# SSE310 register map
Vendor: ARM Ltd.; Series: ARMv8.1-M Mainline; File version: 1.0
CPU: CM85 r0p0, little endian, MPU, FPU, 3 interrupt priority bits, 8 SAU regions
Registers are 32-bit, read-write, reset 0x0 unless marked. A register's access mark holds for its fields unless they carry their own. Offsets are from the block's base; [hi:lo] are bit positions; {n}, {i} and the like mark numbered series; 'fields as' and 'values as' point back to an identical list.

## SYSCONTROL — System Control
Base 0x58021000
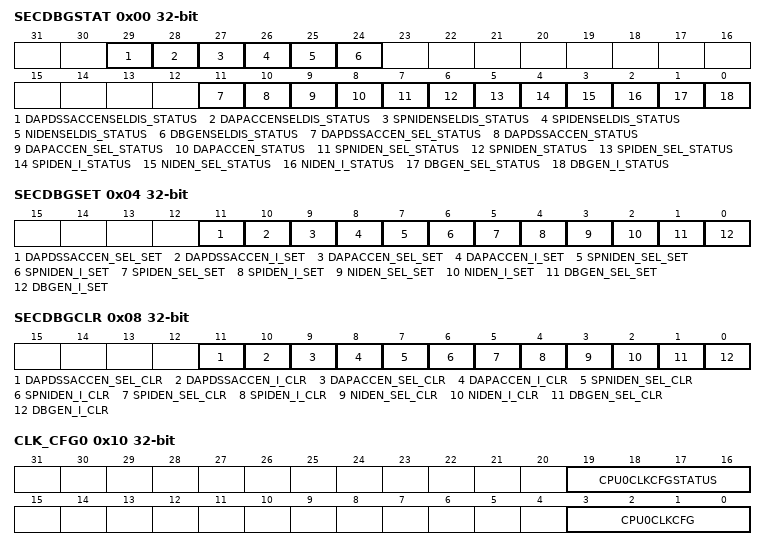
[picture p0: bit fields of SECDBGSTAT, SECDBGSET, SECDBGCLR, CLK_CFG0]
0x00 SECDBGSTAT ro — Secure Debug Configuration Status
  [29] DAPDSSACCENSELDIS_STATUS — Returns the DAPDSSACCENSELDIS configuration value when read.
    1=enable (Secure privilege non-invasive debug enable selector); 0=disable (Secure privilege non-invasive debug disable selector)
  [28] DAPACCENSELDIS_STATUS — Returns the DAPACCENSELDIS configuration value when read.
    values as DAPDSSACCENSELDIS_STATUS
  [27] SPNIDENSELDIS_STATUS — Returns the SPNIDENSELDIS configuration value when read.
    values as DAPDSSACCENSELDIS_STATUS
  [26] SPIDENSELDIS_STATUS — Returns the SPIDENSELDIS configuration value when read.
    values as DAPDSSACCENSELDIS_STATUS
  [25] NIDENSELDIS_STATUS — Returns the NIDENSELDIS configuration value when read.
    values as DAPDSSACCENSELDIS_STATUS
  [24] DBGENSELDIS_STATUS — Returns the DBGENSELDIS configuration value when read.
    values as DAPDSSACCENSELDIS_STATUS
  [11] DAPDSSACCEN_SEL_STATUS — Active High DAP to Debug Subsystem Access Enable Selector Value. This bit returns the DAPDSSACCEN_SEL value. Forced to Zero if DAPDSSACCENSELDIS = 1.
    values as DAPDSSACCENSELDIS_STATUS
  [10] DAPDSSACCEN_STATUS — Active High DAP to Debug Subsystem Access Enable Value. This bit reflects the value on the DAPDSSACCEN pin.
    values as DAPDSSACCENSELDIS_STATUS
  [9] DAPACCEN_SEL_STATUS — Active High DAP Access Enable Selector Value. This bit returns the DAPACCEN_SEL value. Forced to Zero if DAPACCENSELDIS = 1.
    values as DAPDSSACCENSELDIS_STATUS
  [8] DAPACCEN_STATUS — Active High DAP Access Enable Value. This bit reflects the value on the DAPACCEN pin.
    values as DAPDSSACCENSELDIS_STATUS
  [7] SPNIDEN_SEL_STATUS — Secure privilege non-invasive debug enable selector value
    values as DAPDSSACCENSELDIS_STATUS
  [6] SPNIDEN_STATUS — Secure privilege non-invasive debug enable value
    1=enable (Secure privilege non-invasive debug enable); 0=disable (Secure privilege non-invasive debug disable)
  [5] SPIDEN_SEL_STATUS — Secure privilege invasive debug enable selector value
    1=enable (Secure privilege invasive debug enable selector); 0=disable (Secure privilege invasive debug disable selector)
  [4] SPIDEN_I_STATUS — Secure privilege invasive debug enable value
    1=enable (Secure privilege invasive debug enable); 0=disable (Secure privilege invasive debug disable)
  [3] NIDEN_SEL_STATUS — Non-invasive debug enable selector value
    1=enable (non-invasive debug enable selector); 0=disable (non-invasive debug disable selector)
  [2] NIDEN_I_STATUS — Non-invasive debug enable value
    1=enable (non-invasive debug enable); 0=disable (non-invasive debug disable)
  [1] DBGEN_SEL_STATUS — Debug enable selector value
    1=enable (debug enable selector); 0=disable (debug disable selector)
  [0] DBGEN_I_STATUS — Debug enable value
    1=enable (debug enable); 0=disable (debug disable)
0x04 SECDBGSET wo — Secure Debug Configuration Set
  [11] DAPDSSACCEN_SEL_SET — Set Active High DAP to Debug Subsystem Access Enable Selector. Write HIGH to set DAPDSSACCEN_SEL. RAZWI if DAPDSSACCENSELDIS = 1.
    values as SECDBGSTAT.DAPDSSACCENSELDIS_STATUS
  [10] DAPDSSACCEN_I_SET — Set internal version of Active High DAP to Debug Subsystem Access Enable. Write HIGH to set DAPDSSACCEN_I. When read returns DAPDSSACCEN_I. RAZWI if DAPDSSACCENSELDIS = 1.
    values as SECDBGSTAT.DAPDSSACCENSELDIS_STATUS
  [9] DAPACCEN_SEL_SET — Set Active High DAP Access Enable Selector. Write HIGH to set DAPACCEN_SEL. RAZWI if DAPACCENSELDIS = 1.
    values as SECDBGSTAT.DAPDSSACCENSELDIS_STATUS
  [8] DAPACCEN_I_SET — Set internal version of Active High DAP Access Enable. Write HIGH to set DAPACCEN_I. When read returns DAPACCEN_I. RAZWI if DAPACCENSELDIS = 1.
    values as SECDBGSTAT.DAPDSSACCENSELDIS_STATUS
  [7] SPNIDEN_SEL_SET — Secure privilege non-invasive debug enable selector set control
    1=enable (Secure privilege non-invasive debug enable selector set control); 0=disable (Secure privilege non-invasive debug disable selector set control)
  [6] SPNIDEN_I_SET — Secure privilege non-invasive debug enable set control
    1=enable (Secure privilege non-invasive debug enable set control); 0=disable (Secure privilege non-invasive debug disable set control)
  [5] SPIDEN_SEL_SET — Secure privilege invasive debug enable selector set control
    1=enable (Secure privilege invasive debug enable selector set control); 0=disable (Secure privilege invasive debug disable selector set control)
  [4] SPIDEN_I_SET — Secure privilege invasive debug enable set control
    1=enable (Secure privilege invasive debug enable set control); 0=disable (Secure privilege invasive debug disable set control)
  [3] NIDEN_SEL_SET — Non-invasive debug enable selector set control
    1=enable (non-invasive debug enable selector set control); 0=disable (non-invasive debug disable selector set control)
  [2] NIDEN_I_SET — Non-invasive debug enable set control
    1=enable (non-invasive debug enable set control); 0=disable (non-invasive debug disable set control)
  [1] DBGEN_SEL_SET — Debug enable selector set control
    1=enable (debug enable selector set control); 0=disable (debug disable selector set control)
  [0] DBGEN_I_SET — High active debug enable set control
0x08 SECDBGCLR wo — Secure Debug Configuration Clear
  [11] DAPDSSACCEN_SEL_CLR — Clear Active High DAP to Debug Subsystem Access Enable Selector. Write HIGH to clear DAPDSSACCEN_SEL. RAZWI if DAPDSSACCENSELDIS = 1.
    values as SECDBGSTAT.DAPDSSACCENSELDIS_STATUS
  [10] DAPDSSACCEN_I_CLR — Clears internal version of Active High DAP to Debug Subsystem Access Enable. Write HIGH to clear DAPDSSACCEN_I. Always RAZ. WI if DAPDSSACCENSELDIS = 1.
    values as SECDBGSTAT.DAPDSSACCENSELDIS_STATUS
  [9] DAPACCEN_SEL_CLR — Clear Active High DAP Access Enable Selector. Write HIGH to clear DAPACCEN_SEL. RAZWI if DAPACCENSELDIS = 1.
    values as SECDBGSTAT.DAPDSSACCENSELDIS_STATUS
  [8] DAPACCEN_I_CLR — Clear internal version of Active High DAP Access Enable. Write HIGH to clear DAPACCEN_I. When read returns DAPACCEN_I. RAZWI if DAPACCENSELDIS = 1.
    values as SECDBGSTAT.DAPDSSACCENSELDIS_STATUS
  [7] SPNIDEN_SEL_CLR — Secure privilege non-invasive debug enable selector clear control
    1=enable (Secure privilege non-invasive debug enable selector clear control); 0=disable (Secure privilege non-invasive debug disable selector clear control)
  [6] SPNIDEN_I_CLR — Secure privilege non-invasive debug enable clear control
    1=enable (Secure privilege non-invasive debug enable clear control); 0=disable (Secure privilege non-invasive debug disable clear control)
  [5] SPIDEN_SEL_CLR — Secure privilege invasive debug enable selector clear control
    1=enable (Secure privilege invasive debug enable selector clear control); 0=disable (Secure privilege invasive debug disable selector clear control)
  [4] SPIDEN_I_CLR — Secure privilege invasive debug enable clear control
    1=enable (Secure privilege invasive debug enable clear control); 0=disable (Secure privilege invasive debug disable clear control)
  [3] NIDEN_SEL_CLR — Non-invasive debug enable selector clear control
    1=enable (non-invasive debug enable selector clear control); 0=disable (non-invasive debug disable selector clear control)
  [2] NIDEN_I_CLR — Non-invasive debug enable clear control
    1=enable (non-invasive debug enable clear control); 0=disable (non-invasive debug disable clear control)
  [1] DBGEN_SEL_CLR — Debug enable selector clear control
    1=enable (debug enable selector clear control); 0=disable (debug disable selector clear control)
  [0] DBGEN_I_CLR — Debug enable clear control
    1=enable (debug enable clear control); 0=disable (debug disable clear control)
0x0C SCSECCTRL — System Security Control
  [2] SCSECCFGLOCK — Control to disable writes to security-related control registers in this register block
    1=disable (control to disable writes to security-related control registers in this register block); 0=enable (control to enable writes to security-related control registers in this register block)
0x10 CLK_CFG0 — Clock Configuration Register 0.
  [19:16] CPU0CLKCFGSTATUS ro — Clock Configuration Status value that reports the status of clock control for CPU0CLK.
  [3:0] CPU0CLKCFG — Clock Configuration value that drives CPU0CLKCFG signals.
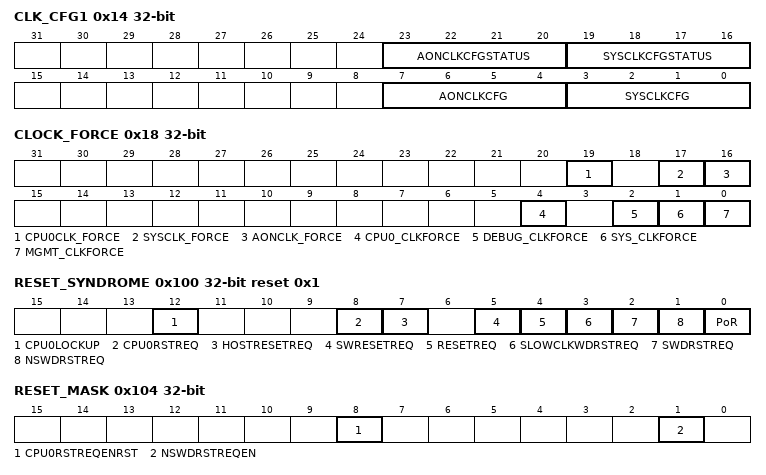
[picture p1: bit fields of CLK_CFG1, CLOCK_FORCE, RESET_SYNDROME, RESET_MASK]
0x14 CLK_CFG1 — Clock Configuration Register 1.
  [23:20] AONCLKCFGSTATUS — Clock Configuration Status value that reports the status of clock control for AONCLK.
  [19:16] SYSCLKCFGSTATUS ro — Clock Configuration Status value that reports the status of clock control for SYSCLK.
  [7:4] AONCLKCFG — Clock Configuration value that drives AONCLKCFG signals.
  [3:0] SYSCLKCFG — Clock Configuration value that drives SYSCLKCFG signals.
0x18 CLOCK_FORCE
  [19] CPU0CLK_FORCE — Set HIGH to request the input CPU0CLK source to stay ON..
  [17] SYSCLK_FORCE — Set HIGH to request the input SYSCLK source to stay ON.
  [16] AONCLK_FORCE — Set HIGH to request the input AONCLK source to stay ON.
  [4] CPU0_CLKFORCE — Set HIGH to force PD_CPU0 Local clocks to run.
  [2] DEBUG_CLKFORCE — Set HIGH to force all clocks in PD_DEBUG to run.
  [1] SYS_CLKFORCE — Set HIGH to force all clocks in PD_SYS to run.
  [0] MGMT_CLKFORCE — Set HIGH to force all clocks in PD_AON domain that runs on SYSCLK to run.
0x100 RESET_SYNDROME reset 0x1
  [12] CPU0LOCKUP wo — CPU 0 Lockup Status.
  [8] CPU0RSTREQ wo — CPU 0 Warm Reset Request.
  [7] HOSTRESETREQ wo — Host Level Cold Reset Request Input.
  [5] SWRESETREQ wo — Software Cold Reset Request.
  [4] RESETREQ wo — Subsystem Hardware Cold Reset Request Input.
  [3] SLOWCLKWDRSTREQ wo — SLOWCLK Watchdog Cold Reset Request.
  [2] SWDRSTREQ wo — Secure Watchdog Cold Reset Request.
  [1] NSWDRSTREQ wo — Non-Secure Watchdog Cold Reset Request.
  [0] PoR wo — Power-on
0x104 RESET_MASK
  [8] CPU0RSTREQENRST — CPU 0 Warm Reset Request Enable.
    1=enabled (Enable Merging CPU 0 System Reset Request); 0=Disabled Merging CPU 0 System Reset Request
  [1] NSWDRSTREQEN — Enable NON-SECURE WATCHDOG Reset
    1=enabled (Enable NON-SECURE WATCHDOG Reset); 0=Disabled NON-SECURE WATCHDOG Reset
0x108 SWRESET wo — Software Reset
  [9] SWRESETREQ — High Active Software Reset Request
0x10C GRETREG — General Purpose Retention
  [15:0] GRETREG — General Purpose Retention Register
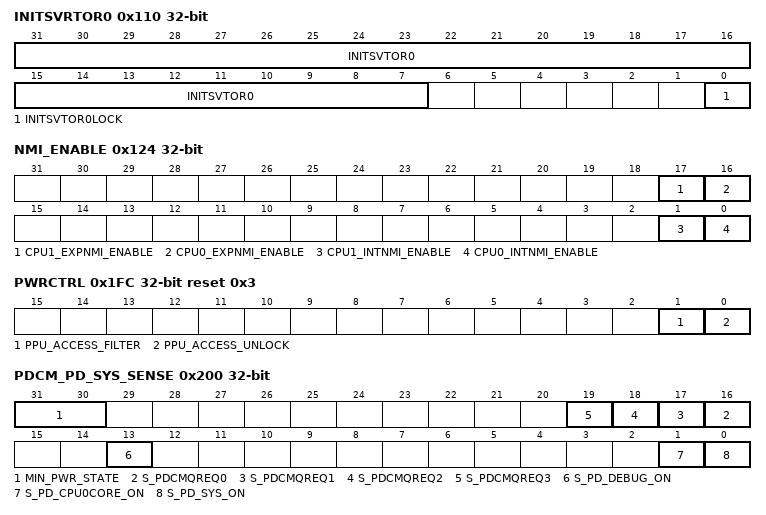
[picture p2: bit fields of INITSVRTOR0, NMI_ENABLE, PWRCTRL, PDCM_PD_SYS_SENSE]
0x110 INITSVRTOR0 — Initial Secure Reset Vector Register For CPU 0
  [31:7] INITSVTOR0 — Default Secure Vector table offset at reset for CPU 0
  [0] INITSVTOR0LOCK wo — Lock INITSVTOR0. When set to 1, will stop any further writes to INITSVTOR0 and INITSVTOR0LOCK fields. Cleared only by Warm reset.
0x120 CPUWAIT — CPU Boot wait control after reset
  [0] CPU0WAIT — CPU 0 waits at boot and whether CPU1 powers up
    0=normally_or_powerup (CPU0 boot normally. From Power ON reset, nSRST reset or Watchdog Reset, CPU 1 powers up); 1=wait_or_no_powerup (CPU0 wait. From Power ON reset, nSRST reset or Watchdog Reset, CPU 1 do not power up)
0x124 NMI_ENABLE
  [17] CPU1_EXPNMI_ENABLE — CPU1 Externally Sourced NMI Enable
    1=enable (CPU1 Externally Sourced NMI Enabled); 0=disabled (CPU1 Externally Sourced NMI Disabled)
  [16] CPU0_EXPNMI_ENABLE — CPU0 Externally Sourced NMI Enable
    1=enable (CPU0 Externally Sourced NMI Enabled); 0=disabled (CPU0 Externally Sourced NMI Disabled)
  [1] CPU1_INTNMI_ENABLE — CPU1 Internally Sourced NMI Enable
    1=enable (CPU1 Internally Sourced NMI Enabled); 0=disabled (CPU1 Internally Sourced NMI Disabled)
  [0] CPU0_INTNMI_ENABLE — CPU0 Internally Sourced NMI Enable
    1=enable (CPU0 Internally Sourced NMI Enabled); 0=disabled (CPU0 Internally Sourced NMI Disabled)
0x1FC PWRCTRL reset 0x3 — Power Configuration and Control.
  [1] PPU_ACCESS_FILTER — Filter Access to PPU Registers. When set to '1' only key PPU interrupt handling registers are open to write access, and all other PPU registers are read only. When set to '0' releases all PPU register to full access.
  [0] PPU_ACCESS_UNLOCK wo — PPU_ACCESS_FILTER write unlock. When 1, Both PPU_ACCESS_FILTER and this register bits can be written. When set to '0' the PPU_ACCESS_FILTER and this register bit will no longer writable, and PPU_ACCESS_UNLOCK will stay '0'.
0x200 PDCM_PD_SYS_SENSE — External Wakeup Control
  [31:30] MIN_PWR_STATE — Defines the Minimum Power State, when PD_SYS is trying to enter a lower power state.
  [n+16] S_PDCMQREQ{n} (n=0..3) — Enable PDCMQREQn[{n}] signal Sensitivity
    1=Enable PDCMQREQn[{n}] signal Sensitivity; 0=disabled (Disable PDCMQREQn[{n}] signal Sensitivity.)
  [13] S_PD_DEBUG_ON ro — Tied to LOW
  [1] S_PD_CPU0CORE_ON ro — Tied to HIGH
    1=high (PD_SYS always tries to stay ON if PD_CPU0CORE is ON)
  [0] S_PD_SYS_ON — Enable PD_SYS ON Sensitivity
    1=enable (Keep PD_SYS awake after powered ON)
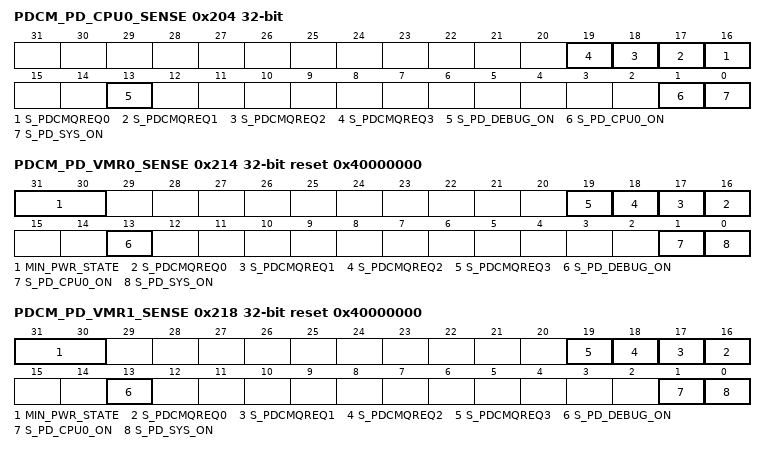
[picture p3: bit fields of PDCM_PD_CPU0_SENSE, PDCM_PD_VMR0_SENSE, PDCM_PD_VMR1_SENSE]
0x204 PDCM_PD_CPU0_SENSE — PDCM PD_CPU0 Sensitivity.
  [n+16] S_PDCMQREQ{n} (n=0..3) — PDCMQREQn[{n}] Tied to LOW
  [13] S_PD_DEBUG_ON ro — Tied to LOW
  [1] S_PD_CPU0_ON ro — Tied to LOW
  [0] S_PD_SYS_ON — Enable PD_SYS ON Sensitivity
    1=enable (Keep PD_SYS awake after powered ON)
0x214 PDCM_PD_VMR0_SENSE reset 0x40000000 — PDCM PD_VMR0 Sensitivity.
  [31:30] MIN_PWR_STATE — Defines the Minimum Power State, when PD_SYS is trying to enter a lower power state.
  [n+16] S_PDCMQREQ{n} (n=0..3) — Enable PDCMQREQn[{n}] signal Sensitivity
    values as PDCM_PD_SYS_SENSE.S_PDCMQREQ0
  [13] S_PD_DEBUG_ON ro — Tied to LOW
  [1] S_PD_CPU0_ON ro — Tied to HIGH
    1=high (PD_SYS always tries to stay ON if PD_CPU0CORE is ON)
  [0] S_PD_SYS_ON — Enable PD_SYS ON Sensitivity
    1=enable (Keep PD_SYS awake after powered ON)
0x218 PDCM_PD_VMR1_SENSE reset 0x40000000 — PDCM PD_VMR1 Sensitivity.
  fields as PDCM_PD_VMR0_SENSE
0xFD0 PIDR4 ro reset 0x4 — Peripheral ID 4
0xFE0 PIDR0 ro reset 0x54 — Peripheral ID 0
0xFE4 PIDR1 ro reset 0xB8 — Peripheral ID 1
0xFE8 PIDR2 ro reset 0x1B — Peripheral ID 2
0xFEC PIDR3 ro — Peripheral ID 3
0xFF0 CIDR0 ro reset 0xD — Component ID 0
0xFF4 CIDR1 ro reset 0xF0 — Component ID 1
0xFF8 CIDR2 ro reset 0x5 — Component ID 2
0xFFC CIDR3 ro reset 0xB1 — Component ID 3

## Notices in the file
Copyright (C) 2012-2022 ARM Limited. All rights reserved.
Purpose: System Viewer Description (SVD) Example (Schema Version 1.1)
This is a description of a none-existent and incomplete device
for demonstration purposes only.
Redistribution and use in source and binary forms, with or without
modification, are permitted provided that the following conditions are met:
- Redistributions of source code must retain the above copyright
notice, this list of conditions and the following disclaimer.
- Redistributions in binary form must reproduce the above copyright
notice, this list of conditions and the following disclaimer in the
documentation and/or other materials provided with the distribution.
- Neither the name of ARM nor the names of its contributors may be used
to endorse or promote products derived from this software without
specific prior written permission.
THIS SOFTWARE IS PROVIDED BY THE COPYRIGHT HOLDERS AND CONTRIBUTORS "AS IS"
AND ANY EXPRESS OR IMPLIED WARRANTIES, INCLUDING, BUT NOT LIMITED TO, THE
IMPLIED WARRANTIES OF MERCHANTABILITY AND FITNESS FOR A PARTICULAR PURPOSE
ARE DISCLAIMED. IN NO EVENT SHALL COPYRIGHT HOLDERS AND CONTRIBUTORS BE
LIABLE FOR ANY DIRECT, INDIRECT, INCIDENTAL, SPECIAL, EXEMPLARY, OR
CONSEQUENTIAL DAMAGES (INCLUDING, BUT NOT LIMITED TO, PROCUREMENT OF
SUBSTITUTE GOODS OR SERVICES; LOSS OF USE, DATA, OR PROFITS; OR BUSINESS
INTERRUPTION) HOWEVER CAUSED AND ON ANY THEORY OF LIABILITY, WHETHER IN
CONTRACT, STRICT LIABILITY, OR TORT (INCLUDING NEGLIGENCE OR OTHERWISE)
ARISING IN ANY WAY OUT OF THE USE OF THIS SOFTWARE, EVEN IF ADVISED OF THE
POSSIBILITY OF SUCH DAMAGE.
